# nrf7140_sysctrl register map
Vendor: Nordic Semiconductor; Series: nRF71; File version: 1
Registers are 32-bit, read-write, reset 0x0 unless marked. A register's access mark holds for its fields unless they carry their own. Offsets are from the block's base; [hi:lo] are bit positions; lines under a group give offsets from that group; 'fields as' and 'values as' point back to an identical list.

## VREG1V0
Base 0x5F963000
0x100 EVENTS_READY — Power up done
  [0] EVENTS_READY
    0=NotGenerated (Event not generated); 1=Generated (Event generated)
0x104 EVENTS_SETTLED — Settled flag for MODE handshake
  [0] EVENTS_SETTLED
    values as EVENTS_READY.EVENTS_READY
0x108 EVENTS_IOUTCMP — Analog current comparator
  [0] EVENTS_IOUTCMP
    values as EVENTS_READY.EVENTS_READY
0x10C EVENTS_LP2HP — Current consumption above threshold
  [0] EVENTS_LP2HP
    values as EVENTS_READY.EVENTS_READY
0x110 EVENTS_HP2LP — Current consumption below threshold
  [0] EVENTS_HP2LP
    values as EVENTS_READY.EVENTS_READY
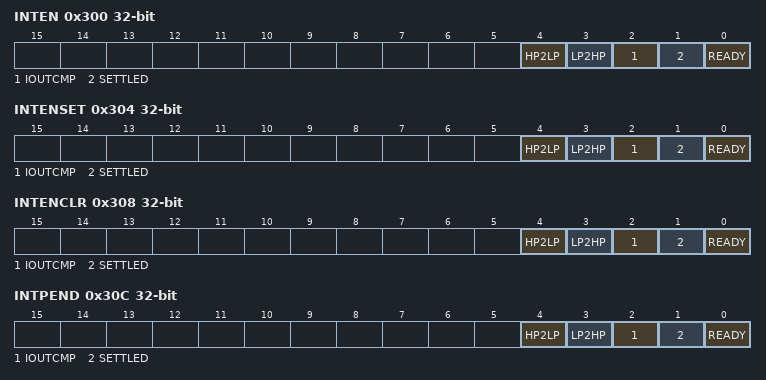
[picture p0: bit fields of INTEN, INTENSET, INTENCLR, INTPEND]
0x300 INTEN — Enable or disable interrupt
  [all] fields
    0=Disabled; 1=Enabled
  [4] HP2LP — Enable or disable interrupt for event HP2LP
  [3] LP2HP — Enable or disable interrupt for event LP2HP
  [2] IOUTCMP — Enable or disable interrupt for event IOUTCMP
  [1] SETTLED — Enable or disable interrupt for event SETTLED
  [0] READY — Enable or disable interrupt for event READY
0x304 INTENSET — Enable interrupt
  [all] fields
    on read: 0=Disabled (Read: Disabled); 1=Enabled (Read: Enabled) | on write: 1=Set (Enable)
  [4] HP2LP — Write '1' to enable interrupt for event HP2LP
  [3] LP2HP — Write '1' to enable interrupt for event LP2HP
  [2] IOUTCMP — Write '1' to enable interrupt for event IOUTCMP
  [1] SETTLED — Write '1' to enable interrupt for event SETTLED
  [0] READY — Write '1' to enable interrupt for event READY
0x308 INTENCLR — Disable interrupt
  [all] fields
    on read: 0=Disabled (Read: Disabled); 1=Enabled (Read: Enabled) | on write: 1=Clear (Disable)
  [4] HP2LP — Write '1' to disable interrupt for event HP2LP
  [3] LP2HP — Write '1' to disable interrupt for event LP2HP
  [2] IOUTCMP — Write '1' to disable interrupt for event IOUTCMP
  [1] SETTLED — Write '1' to disable interrupt for event SETTLED
  [0] READY — Write '1' to disable interrupt for event READY
0x30C INTPEND ro — Pending interrupts
  [all] fields
    on read: 0=NotPending (Read: Not pending); 1=Pending (Read: Pending)
  [4] HP2LP — Read pending status of interrupt for event HP2LP
  [3] LP2HP — Read pending status of interrupt for event LP2HP
  [2] IOUTCMP — Read pending status of interrupt for event IOUTCMP
  [1] SETTLED — Read pending status of interrupt for event SETTLED
  [0] READY — Read pending status of interrupt for event READY
0x400 STATUS ro — Voltage regulator status
  [1:0] MODE — Current voltage regulator mode
    0=High power mode; 1=Low power mode; 2=Ultra-low power refresh mode
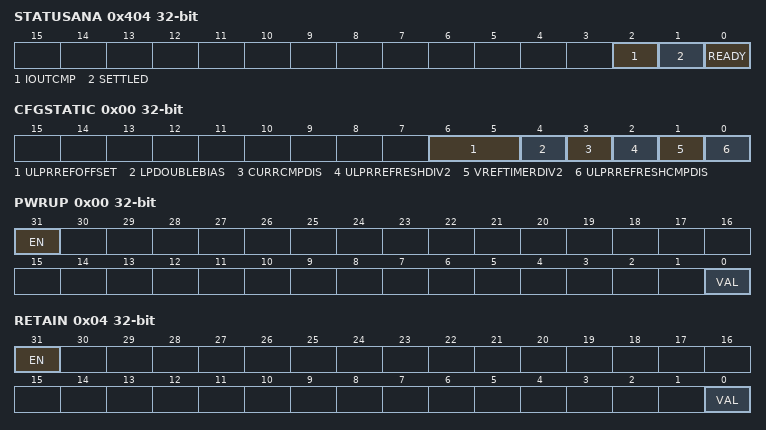
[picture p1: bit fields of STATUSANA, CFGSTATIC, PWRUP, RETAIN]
0x404 STATUSANA ro — Status of analog module output signals
  [2] IOUTCMP — Current value of the IOUTCMP signal from the analog module
  [1] SETTLED — Current value of the SETTLED signal from the analog module
  [0] READY — Current value of the READY signal from the analog module
0x410 CONFIG group — Unspecified
  0x00 CFGSTATIC — Voltage regulator static CFG configuration
    [6:5] ULPRREFOFFSET — Offset of voltage reference in ULPR mode.
      0=VRO00mV (0mV); 1=VRO10mV (10mV); 2=VRO20mV (20mV); 3=VRO30mV (30mV)
    [4] LPDOUBLEBIAS — Double the LP core bias current
      0=Disabled (Configuration disabled); 1=Enabled (Configuration enabled)
    [3] CURRCMPDIS — Disable the current comparator
      values as LPDOUBLEBIAS
    [2] ULPRREFRESHDIV2 — Double the ULPR refresh timer
      values as LPDOUBLEBIAS
    [1] VREFTIMERDIV2 — Double the VREF timer
      values as LPDOUBLEBIAS
    [0] ULPRREFRESHCMPDIS — Disable the ULPR refresh comparator
      values as LPDOUBLEBIAS
  0x04 CFGDYNAMIC reset 0x4 — Voltage regulator dynamic CFG configuration
    [2:0] SOFTSTART — Current limit configuration for the voltage regulator
      0=Automatically handled by the peripheral; 1=Normal operation; 2=IlimHigh (Radio soft start); 3=IlimMid (WU soft start); 4=IlimLow (Reset current limit)
0x440 TRIM group — Unspecified
  0x00 IREF reset 0x8 — Local current reference trimming
    [6:0] VAL — Current reference trimming value
  0x04 HIGHPOWER — High power mode output voltage offset trimming
    [3:0] VAL — Voltage offset trimming value
  0x08 LOWPOWER — Low power mode output voltage offset trimming
    [3:0] VAL — Voltage offset trimming value.
  0x0C ULPR — ULPR mode comparator offset trimming
    [2:0] VAL — Comparator offset trimming value.
0x480 MIRROR reset 0x1 — Enable LOCK for mirrored registers
  [0] LOCK — Lock for mirrored registers
    0=Disabled (Lock disabled); 1=Enabled (Lock enabled)
0x484 VOUTHPNOMINAL reset 0x21 — Nominal high power mode output voltage programming
  [5:0] VAL — Output voltage value
0x488 VOUTHPRADIO reset 0x2B — Radio high power mode output voltage programming
  [5:0] VAL — Output voltage value
0x48C VOUTHPHELPER reset 0x27 — High power helper mode output voltage programming
  [5:0] VAL — Output voltage value
0x490 VOUTLPNOMINAL reset 0x18 — Nominal low power mode output voltage programming
  [5:0] VAL — Output voltage value
0x494 VOUTLPRADIO reset 0x27 — Radio low power mode output voltage programming
  [5:0] VAL — Output voltage value
0x498 VOUTULV reset 0x8 — ULV output voltage programming
  [5:0] VAL — Output voltage value
0x49C MODE — Voltage regulator mode
  [1:0] MODE
    0=Automatically handled by the peripheral; 1=High power mode; 2=Low power mode; 3=Ultra-low power refresh mode
0x4A0 ITHRESHOLD reset 0xA — Current threshold for mode transistion
  [3:0] VAL — Current consumption
0x4A4 VOUTHPHELPERRADIO reset 0x27 — Radio high power helper mode output voltage programming
  [5:0] VAL — Output voltage value
0x4A8 VOUTHPHELPERWIFI reset 0x31 — Wi-Fi high power helper mode output voltage programming
  [5:0] VAL — Output voltage value
0x500 OVERRIDE group — Unspecified
  0x00 PWRUP — Override the PWRUP signal to the analog module
    [31] EN — Enable the override
      0=Disabled (Override is disabled); 1=Enabled (Override is enabled)
    [0] VAL — Override value for the signal
  0x04 RETAIN — Override the RETAIN signal to the analog module
    fields as OVERRIDE.PWRUP
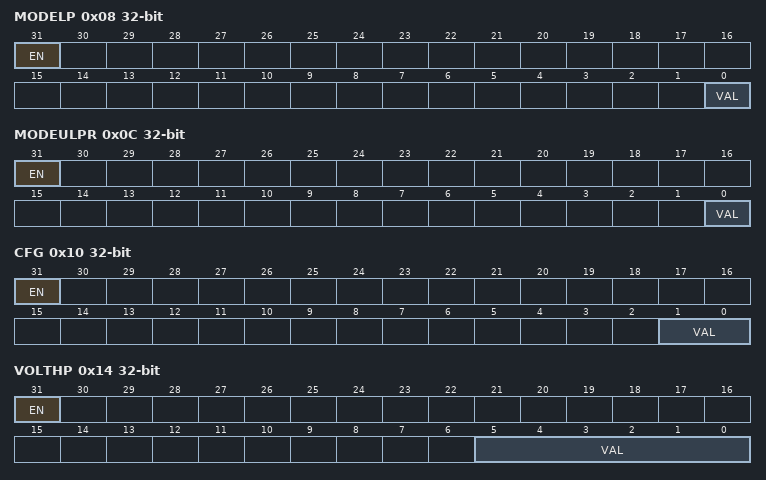
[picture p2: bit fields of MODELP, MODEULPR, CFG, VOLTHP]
  0x08 MODELP — Override the MODE LP signal to the analog module
    fields as OVERRIDE.PWRUP
  0x0C MODEULPR — Override the MODE ULPR signal to the analog module
    fields as OVERRIDE.PWRUP
  0x10 CFG — Override the dynamic CFG signal to the analog module
    [31] EN — Enable the override
      values as OVERRIDE.PWRUP.EN
    [1:0] VAL — Override value for the signal
  0x14 VOLTHP — Override the VOLT HP signal to the analog module
    [31] EN — Enable the override
      values as OVERRIDE.PWRUP.EN
    [5:0] VAL — Override value for the signal
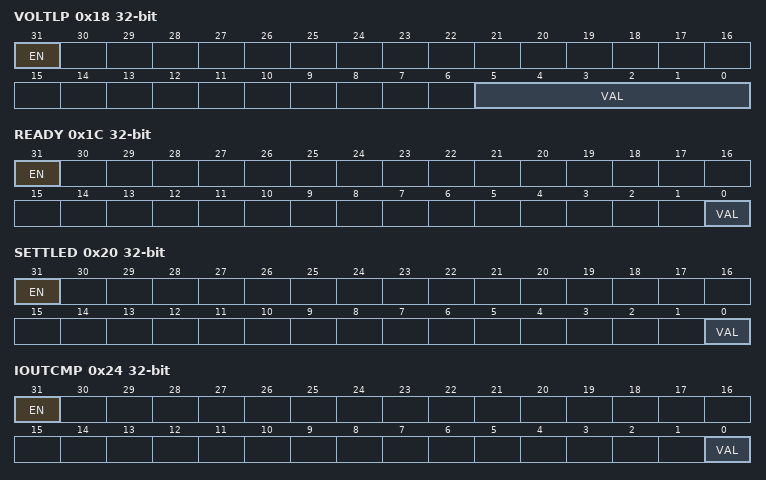
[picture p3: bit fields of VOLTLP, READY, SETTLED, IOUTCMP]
  0x18 VOLTLP — Override the VOLT LP signal to the analog module
    fields as OVERRIDE.VOLTHP
  0x1C READY — Override the READY signal from the analog module
    [31] EN — Enable the override
      values as OVERRIDE.PWRUP.EN
    [0] VAL — Current value of the signal
  0x20 SETTLED — Override the SETTLED signal from the analog module
    fields as OVERRIDE.READY
  0x24 IOUTCMP — Override the IOUTCMP signal from the analog module
    fields as OVERRIDE.READY
0x600 DFT group — Unspecified
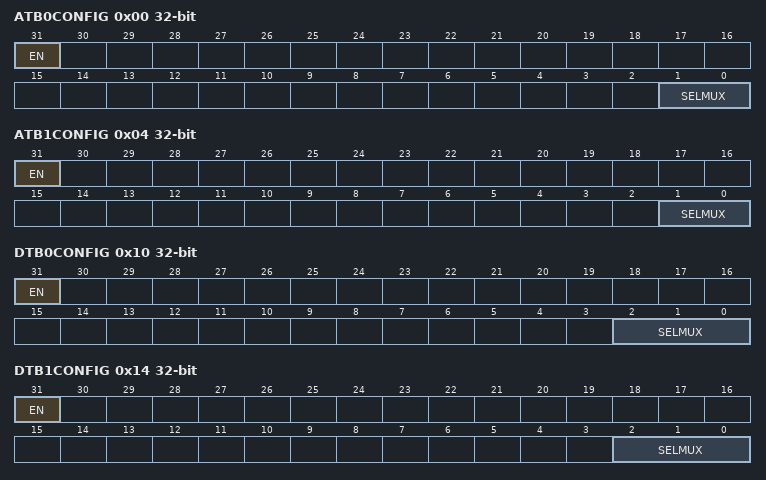
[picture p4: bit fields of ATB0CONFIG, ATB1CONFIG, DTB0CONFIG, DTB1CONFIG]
  0x00 ATB0CONFIG — Analog Test Bus 0 (ATB0) configuration
    [31] EN — Enable the analog test bus
      0=Disabled (Analog test bus is disabled); 1=Enabled (Analog test bus is enabled)
    [1:0] SELMUX — Select multiplexer for ATB0
      0=ExtVref (Negative input of calibration comparator); 1=Ibpp50n (Internal 50nA current reference); 2=ibpsr8u (Internal 8uA current reference); 3=VSS
  0x04 ATB1CONFIG — Analog Test Bus 1 (ATB1) configuration
    [31] EN — Enable the analog test bus
      values as DFT.ATB0CONFIG.EN
    [1:0] SELMUX — Select multiplexer for ATB1
      0=None selected; 1=BufferedHPvref; 2=VDD1V0; 3=Ibpsr4u (Internal 4uA current reference, through 225kOhm resistor)
  0x10 DTB0CONFIG — Digital Test Bus 0 (DTB0) configuration
    [31] EN — Enable the digital test bus
      0=Disabled (Digital test bus is disabled); 1=Enabled (Digital test bus is enabled)
    [2:0] SELMUX — Select multiplexer for DTB0
      0=None selected, logic 0; 1=RefreshULPR (ULPR refresh pulse); 2=SettledIBPSR (BIAS_IBPSR_4U_DVT settled signal); 4=CurrCmp (Current comparator output); 5=ReqModeLP (LP mode request); 6=RegModeULPR (ULPR mode request); 7=CalCmp (Calibration comparator output)
  0x14 DTB1CONFIG — Digital Test Bus 1 (DTB1) configuration
    [31] EN — Enable the digital test bus
      values as DFT.DTB0CONFIG.EN
    [2:0] SELMUX — Select multiplexer for DTB1
      0=Vref timer acknowledge; 1=RefreshTimerAck (ULPR refresh timer acknowledge); 2=ReadyIBPSR (IBPSR ready signal); 3=ReadyHP (High power core ready signal); 4=ReadyLP (Low power core ready signal); 5=CancelLPAck (Low power core cancel acknowledge signal); 6=ReadyIBPP5n (BIAS_IBPP_5N ready signal); 7=Settled signal
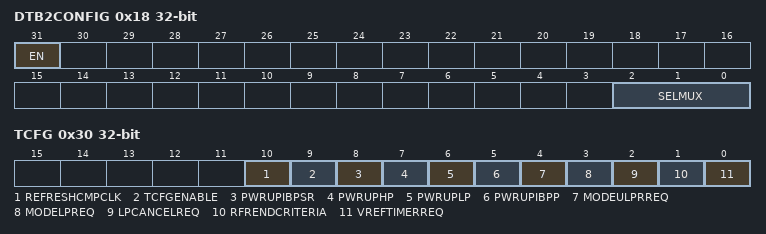
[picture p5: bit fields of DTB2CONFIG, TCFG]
  0x18 DTB2CONFIG — Digital Test Bus 2 (DTB2) configuration
    [31] EN — Enable the digital test bus
      values as DFT.DTB0CONFIG.EN
    [2:0] SELMUX — Select multiplexer for DTB2
      0=Vref timer request; 1=RefreshTimerReq (ULPR refresh timer request); 2=PwrupIBPSR (IBPSR power up signal); 3=PwrupHP (High power core power up signal); 4=PwrupLP (Low power core power up signal); 5=CancelLP (Low power core cancel signal); 6=PwrupIBPP5n (BIAS_IBPP_5N power up signal); 7=None selected, logic 0
  0x1C DTB3CONFIG — Digital Test Bus 3 (DTB3) configuration
    [27] PWRUPDELTEST — Enable the PWRUP delay test circuit
      0=Disabled (PWRUP delay test circuit is disabled); 1=Enabled (PWRUP delay test circuit is enabled)
  0x30 TCFG — Test mode configuration
    [10] REFRESHCMPCLK — Controls clock input of refresh comparator
    [9] TCFGENABLE — Enable TCFG control
    [8] PWRUPIBPSR — Controls PWRUP_IBPSR_BIAS_SW_1V8
    [7] PWRUPHP — Controls PWRUP_LDO_HP_AO_1V8
    [6] PWRUPLP — Controls PWRUP_LDO_LP_AO_1V8
    [5] PWRUPIBPP — Controls PWRUP_IBPP_BIAS_SW_1V8
    [4] MODEULPRREQ — Controls MODE_ULPR_REQ_SW_1V8
    [3] MODELPREQ — Controls MODE_LP_REQ_SW_1V8
    [2] LPCANCELREQ — Controls LDP_LP_CANCEL_REQ_AO_1V8
    [1] RFRENDCRITERIA — Controls RFR_END_CRITERIA_REQ_SW_1V8
    [0] VREFTIMERREQ — Controls VREF_TIMER_REQ_SW_1V8
  0x34 CALEN — Calibration enable
    [0] CALEN
      0=ATCMPOff; 1=ATCMPOn
  0x38 CALCMP ro — Calibration compare
    [0] CALCMP
